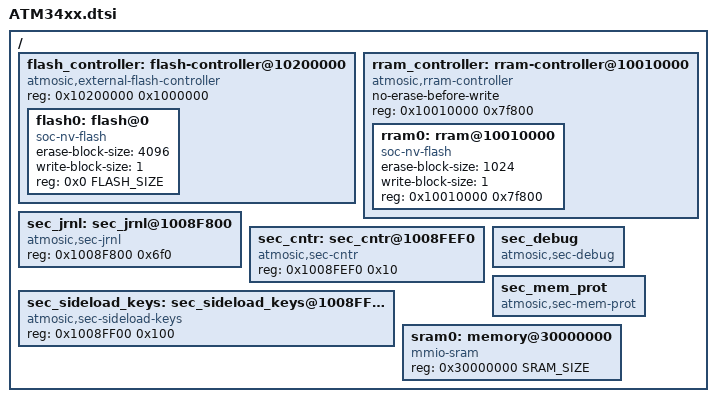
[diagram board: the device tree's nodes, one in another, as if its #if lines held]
/*
 * Copyright (c) 2021-2025 Atmosic
 *
 * SPDX-License-Identifier: Apache-2.0
 */

#include <arm/atmosic/ATM34.dtsi>

#ifndef FLASH_SIZE
#define FLASH_SIZE 0x80000
#endif

#if defined(ATM_SPE_SIZE) && (ATM_SPE_SIZE == 0)
#define SRAM_SIZE 0x20000
#else
#if defined(RUN_IN_FLASH) && (RUN_IN_FLASH == 2)
#define SRAM_SIZE 0x1000
#else
#define SRAM_SIZE 0x4000
#endif
#endif // ATM_SPE_SIZE

/ {
	flash_controller: flash-controller@10200000 {
		compatible = "atmosic,external-flash-controller";

		#address-cells = <1>;
		#size-cells = <1>;

		reg = <0x10200000 0x1000000>;
		ranges = <0x0 0x10200000 0x1000000>;

		flash0: flash@0 {
			compatible = "soc-nv-flash";
			erase-block-size = <4096>;
			write-block-size = <1>;
			reg = <0x0 FLASH_SIZE>;
		};
	};

	rram_controller: rram-controller@10010000 {
		compatible = "atmosic,rram-controller";
		no-erase-before-write;

		#address-cells = <1>;
		#size-cells = <1>;

		reg = <0x10010000 0x7f800>;

		rram0: rram@10010000 {
			compatible = "soc-nv-flash";
			erase-block-size = <1024>;
			write-block-size = <1>;
			reg = <0x10010000 0x7f800>;
		};
	};

	sec_jrnl: sec_jrnl@1008F800 {
		compatible = "atmosic,sec-jrnl";

		#address-cells = <1>;
		#size-cells = <1>;

		reg = <0x1008F800 0x6f0>;
		status = "okay";
	};

	sec_cntr: sec_cntr@1008FEF0 {
		compatible = "atmosic,sec-cntr";

		#address-cells = <1>;
		#size-cells = <1>;

		reg = <0x1008FEF0 0x10>;
		status = "okay";
	};

	sec_sideload_keys: sec_sideload_keys@1008FF00 {
		compatible = "atmosic,sec-sideload-keys";

		#address-cells = <1>;
		#size-cells = <1>;

		reg = <0x1008FF00 0x100>;
		status = "okay";
	};

	sec_debug: sec_debug {
		compatible = "atmosic,sec-debug";
		status = "okay";
	};

	sec_mem_prot: sec_mem_prot {
		compatible = "atmosic,sec-mem-prot";
		status = "okay";
	};

	sram0: memory@30000000 {
		device_type = "memory";
		compatible = "mmio-sram";
		reg = <0x30000000 SRAM_SIZE>;
	};
};

#include "ATM34xx_partitions.dtsi"
